# DA1470x register map
Vendor: Dialog; Series: DA1470x; File version: 1.2
CPU: CM33 r0p2, little endian, MPU, FPU, DSP, VTOR, 4 interrupt priority bits
Registers are 32-bit, read-write, reset 0x0 unless marked. A register's access mark holds for its fields unless they carry their own. Offsets are from the block's base; [hi:lo] are bit positions; {n}, {i} and the like mark numbered series.

## MEMCTRL — MEMCTRL registers
Base 0x50050000
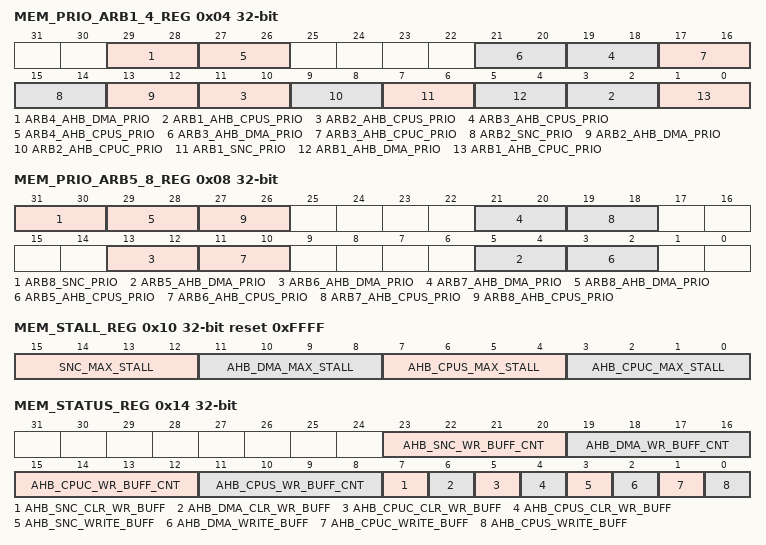
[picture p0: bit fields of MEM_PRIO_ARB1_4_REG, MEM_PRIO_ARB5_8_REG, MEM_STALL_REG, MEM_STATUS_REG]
0x04 MEM_PRIO_ARB1_4_REG — Priority Control Register for arbiter 1, 2, 3 and 4
  [29:28] ARB4_AHB_DMA_PRIO — Priority for the DMA AHB interface of arbiter 4 00: low priority (default) 01: mid priority 1x: high priority
  [8n-5:8n-6] ARB{n}_AHB_CPUS_PRIO (n=1..4) — Priority for the CPUS AHB interface of arbiter {n}. 00: low priority (default) 01: mid priority 10: high priority 11: top priority
  [21:20] ARB3_AHB_DMA_PRIO — Priority for the DMA AHB interface of arbiter 3 00: low priority (default) 01: mid priority 1x: high priority
  [17:16] ARB3_AHB_CPUC_PRIO — Priority for the CPUC AHB interface of arbiter 3. 00: low priority (default) 01: mid priority 10: high priority 11: top priority
  [15:14] ARB2_SNC_PRIO — Priority for the SNC interface of arbiter 2. 00: low priority (default) 01: mid priority 10: high priority 11: top priority
  [13:12] ARB2_AHB_DMA_PRIO — Priority for the DMA AHB interface of arbiter 2. 00: low priority (default) 01: mid priority 1x: high priority
  [9:8] ARB2_AHB_CPUC_PRIO — Priority for the CPUC AHB interface of arbiter 2. 00: low priority (default) 01: mid priority 10: high priority 11: top priority
  [7:6] ARB1_SNC_PRIO — Priority for the SNC interface of arbiter 1. 00: low priority (default) 01: mid priority 10: high priority 11: top priority
  [5:4] ARB1_AHB_DMA_PRIO — Priority for the DMA AHB interface of arbiter 1. 00: low priority (default) 01: mid priority 1x: high priority
  [1:0] ARB1_AHB_CPUC_PRIO — Priority for the CPUC AHB interface of arbiter 1. 00: low priority (default) 01: mid priority 10: high priority 11: top priority
0x08 MEM_PRIO_ARB5_8_REG (reset mask 0x7FFFFFFF) — Priority Control Register for arbiter 5, 6, 7 and 8
  [31:30] ARB8_SNC_PRIO — Priority for the SNC interface of arbiter 8. 00: low priority (default) 01: mid priority 10: high priority 11: top priority
  [8n-35:8n-36] ARB{n}_AHB_DMA_PRIO (n=5..8) — Priority for the DMA AHB interface of arbiter {n}. 00: low priority (default) 01: mid priority 1x: high priority
  [8n-37:8n-38] ARB{n}_AHB_CPUS_PRIO (n=5..8) — Priority for the CPUS AHB interface of arbiter {n}. 00: low priority (default) 01: mid priority 10: high priority 11: top priority
0x10 MEM_STALL_REG reset 0xFFFF — Maximum Stall cycles Control Register
  [15:12] SNC_MAX_STALL — Maximum allowed number of stall cycles for the SNC interface. If exceeded, the interface will get high priority. Valid for a single access so the next access (of a burst) might end up in the que for the same number of wait cycles. 0: don't use, not feasible and can block other interfaces 1: max 1 stall cycle 15: max 15 stall cycles
  [11:8] AHB_DMA_MAX_STALL — Maximum allowed number of stall cycles for the DMA AHB interface. If exceeded, the interface will get high priority. Valid for a single access so the next access (of a burst) might end up in the que for the same number of wait cycles. 0: don't use, not feasible and can block other interfaces 1: max 1 stall cycle 15: max 15 stall cycles
  [7:4] AHB_CPUS_MAX_STALL — Maximum allowed number of stall cycles for the CPUS AHB interface. If exceeded, the interface will get high priority. Valid for a single access so the next access (of a burst) might end up in the que for the same number of wait cycles. 0: don't use, not feasible and can block other interfaces 1: max 1 stall cycle 15: max 15 stall cycles
  [3:0] AHB_CPUC_MAX_STALL — Maximum allowed number of stall cycles for the CPUC AHB interface. If exceeded, the interface will get high priority. Valid for a single access so the next access (of a burst) might end up in the que for the same number of wait cycles. 0: don't use, not feasible and can block other interfaces 1: max 1 stall cycle 15: max 15 stall cycles
0x14 MEM_STATUS_REG — Memory Arbiter Status Register
  [23:20] AHB_SNC_WR_BUFF_CNT ro — The maximum number of arbiter clock cycles that an SNC AHB access has been buffered.
  [19:16] AHB_DMA_WR_BUFF_CNT ro — The maximum number of arbiter clock cycles that an DMA AHB access has been buffered.
  [15:12] AHB_CPUC_WR_BUFF_CNT ro — The maximum number of arbiter clock cycles that an CPUC AHB access has been buffered.
  [11:8] AHB_CPUS_WR_BUFF_CNT ro — The maximum number of arbiter clock cycles that an CPUS_AHB access has been buffered.
  [7] AHB_SNC_CLR_WR_BUFF wo — Writing a '1' clears AHB_SNC_WR_BUFF_CNT.
  [6] AHB_DMA_CLR_WR_BUFF wo — Writing a '1' clears AHB_DMA_WR_BUFF_CNT.
  [5] AHB_CPUC_CLR_WR_BUFF wo — Writing a '1' clears AHB_CPUC_WR_BUFF_CNT.
  [4] AHB_CPUS_CLR_WR_BUFF wo — Writing a '1' clears AHB_CPUS_WR_BUFF_CNT.
  [3] AHB_SNC_WRITE_BUFF ro — 0: No SNC AHB write access is buffered. 1: Currently a single SNC AHB write access is buffered in the arbiter.
  [2] AHB_DMA_WRITE_BUFF ro — 0: No DMA AHB write access is buffered. 1: Currently a single DMA AHB write access is buffered in the arbiter.
  [1] AHB_CPUC_WRITE_BUFF ro — 0: No CPUC AHB write access is buffered. 1: Currently a single CPUC AHB write access is buffered in the arbiter.
  [0] AHB_CPUS_WRITE_BUFF ro — 0: No CPUS AHB write access is buffered. 1: Currently a single CPUS AHB write access is buffered in the arbiter.
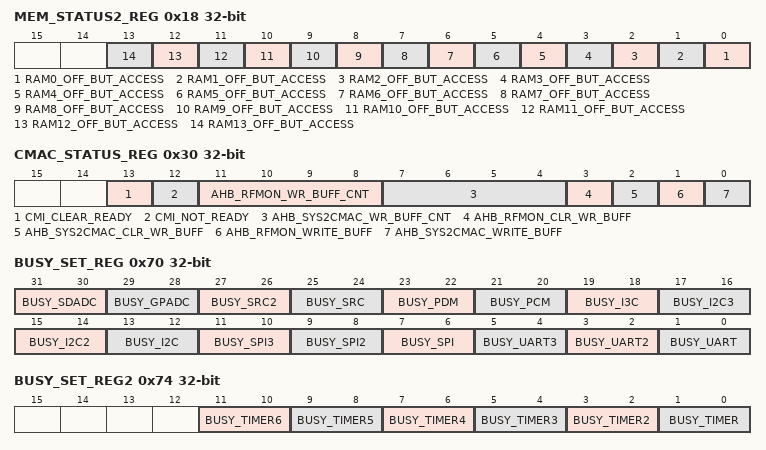
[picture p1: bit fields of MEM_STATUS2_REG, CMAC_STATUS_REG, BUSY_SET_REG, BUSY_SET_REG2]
0x18 MEM_STATUS2_REG — RAM cells Status Register
  [n] RAM{n}_OFF_BUT_ACCESS (n=0..13) — Reading a '1' indicates RAM{n} was off but still access was performed. Writing a '1' will clear the status back to '0'.
0x20 CMI_CODE_BASE_REG — CMAC code Base Address Register
  [19:10] CMI_CODE_BASE_ADDR ro — Base address for CMAC code with steps of 1 kB. 0x001: 1 kB base address 0x010: 16 kB base address 0x100: 256 kB base address
0x24 CMI_DATA_BASE_REG — CMAC data Base Address Register
  [19:2] CMI_DATA_BASE_ADDR — Base address for CMAC data with steps of 4 bytes. Note that the CMAC address scheme is used. 0x00001: 4 byte base address 0x00010: 64 byte base address 0x00100: 1 kB base address 0x01000: 16 kB base address 0x10000: 256 kB base address
0x28 CMI_SHARED_BASE_REG — CMAC shared data Base Address Register
  [19:10] CMI_SHARED_BASE_ADDR — Base address for CMAC shared data with steps of 1 kB. Note that the CMAC address scheme is used and should only be used to point to RAM 9 or 10.. 0x001: 1 kB base address 0x010: 16 kB base address 0x100: 256 kB base address
0x2C CMI_END_REG reset 0xFFFFF — CMAC end Address Register
  [19:10] CMI_END_ADDR — End address for CMAC code and data accesses with steps of 1 kB. Note that the CMAC address scheme is used. 0x000: accesses up to 1kB are allowed 0x001: accesses up to 2kB are allowed 0x01F: accesses up to 32kB are allowed 0x1FF: accesses up to 512kB are allowed
0x30 CMAC_STATUS_REG — Memory Arbiter Status Register
  [13] CMI_CLEAR_READY wo — Writing a '1' clears CMI_NOT_READY bit.
  [12] CMI_NOT_READY ro — 0: Normal operation 1: CMI access performed which couldn't be handled right away (interface doesn't allow wait cycles)
  [11:8] AHB_RFMON_WR_BUFF_CNT ro — The maximum number of arbiter clock cycles that an CPUC AHB access has been buffered.
  [7:4] AHB_SYS2CMAC_WR_BUFF_CNT ro — The maximum number of arbiter clock cycles that an CPUS_AHB access has been buffered.
  [3] AHB_RFMON_CLR_WR_BUFF wo — Writing a '1' clears AHB_CPUC_WR_BUFF_CNT.
  [2] AHB_SYS2CMAC_CLR_WR_BUFF wo — Writing a '1' clears AHB_CPUS_WR_BUFF_CNT.
  [1] AHB_RFMON_WRITE_BUFF ro — 0: No CPUC AHB write access is buffered. 1: Currently a single CPUC AHB write access is buffered in the arbiter.
  [0] AHB_SYS2CMAC_WRITE_BUFF ro — 0: No CPUS AHB write access is buffered. 1: Currently a single CPUS AHB write access is buffered in the arbiter.
0x70 BUSY_SET_REG (reset mask 0x7FFFFFFF) — BSR Set Register
  [31:30] BUSY_SDADC write-once — Writing a non-zero value to this field sets the corresponding BUSY bit, but only if it was not claimed (BUSY=0). Reading returns 0 to allow read/modify/write to the register.
  [29:28] BUSY_GPADC write-once — Writing a non-zero value to this field sets the corresponding BUSY bit, but only if it was not claimed (BUSY=0). Reading returns 0 to allow read/modify/write to the register.
  [27:26] BUSY_SRC2 write-once — Writing a non-zero value to this field sets the corresponding BUSY bit, but only if it was not claimed (BUSY=0). Reading returns 0 to allow read/modify/write to the register.
  [25:24] BUSY_SRC write-once — Writing a non-zero value to this field sets the corresponding BUSY bit, but only if it was not claimed (BUSY=0). Reading returns 0 to allow read/modify/write to the register.
  [23:22] BUSY_PDM write-once — Writing a non-zero value to this field sets the corresponding BUSY bit, but only if it was not claimed (BUSY=0). Reading returns 0 to allow read/modify/write to the register.
  [21:20] BUSY_PCM write-once — Writing a non-zero value to this field sets the corresponding BUSY bit, but only if it was not claimed (BUSY=0). Reading returns 0 to allow read/modify/write to the register.
  [19:18] BUSY_I3C write-once — Writing a non-zero value to this field sets the corresponding BUSY bit, but only if it was not claimed (BUSY=0). Reading returns 0 to allow read/modify/write to the register.
  [17:16] BUSY_I2C3 write-once — Writing a non-zero value to this field sets the corresponding BUSY bit, but only if it was not claimed (BUSY=0). Reading returns 0 to allow read/modify/write to the register.
  [15:14] BUSY_I2C2 write-once — Writing a non-zero value to this field sets the corresponding BUSY bit, but only if it was not claimed (BUSY=0). Reading returns 0 to allow read/modify/write to the register.
  [13:12] BUSY_I2C write-once — Writing a non-zero value to this field sets the corresponding BUSY bit, but only if it was not claimed (BUSY=0). Reading returns 0 to allow read/modify/write to the register.
  [11:10] BUSY_SPI3 write-once — Writing a non-zero value to this field sets the corresponding BUSY bit, but only if it was not claimed (BUSY=0). Reading returns 0 to allow read/modify/write to the register.
  [9:8] BUSY_SPI2 write-once — Writing a non-zero value to this field sets the corresponding BUSY bit, but only if it was not claimed (BUSY=0). Reading returns 0 to allow read/modify/write to the register.
  [7:6] BUSY_SPI write-once — Writing a non-zero value to this field sets the corresponding BUSY bit, but only if it was not claimed (BUSY=0). Reading returns 0 to allow read/modify/write to the register.
  [5:4] BUSY_UART3 write-once — Writing a non-zero value to this field sets the corresponding BUSY bit, but only if it was not claimed (BUSY=0). Reading returns 0 to allow read/modify/write to the register.
  [3:2] BUSY_UART2 write-once — Writing a non-zero value to this field sets the corresponding BUSY bit, but only if it was not claimed (BUSY=0). Reading returns 0 to allow read/modify/write to the register.
  [1:0] BUSY_UART write-once — Writing a non-zero value to this field sets the corresponding BUSY bit, but only if it was not claimed (BUSY=0). Reading returns 0 to allow read/modify/write to the register.
0x74 BUSY_SET_REG2 — BSR2 Set Register
  [2n-1:2n-2] BUSY_TIMER{n} write-once (n=2..6) — Writing a non-zero value to this field sets the corresponding BUSY bit, but only if it was not claimed (BUSY=0). Reading returns 0 to allow read/modify/write to the register.
  [1:0] BUSY_TIMER write-once — Writing a non-zero value to this field sets the corresponding BUSY bit, but only if it was not claimed (BUSY=0). Reading returns 0 to allow read/modify/write to the register.
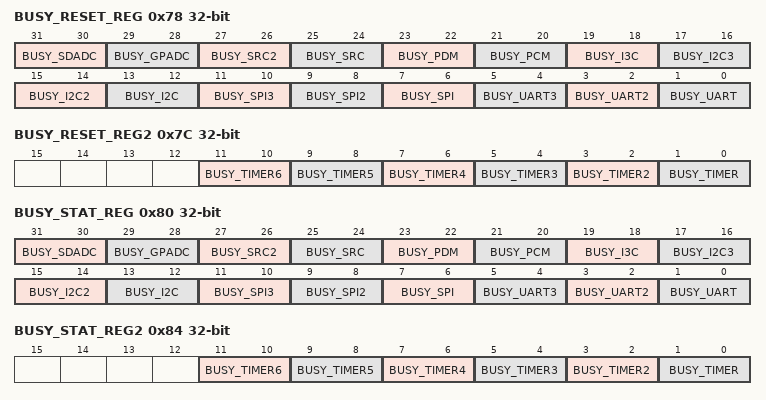
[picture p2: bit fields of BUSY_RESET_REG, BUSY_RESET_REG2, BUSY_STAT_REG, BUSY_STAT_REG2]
0x78 BUSY_RESET_REG (reset mask 0x7FFFFFFF) — BSR Reset Register
  [31:30] BUSY_SDADC — Clear the BUSY bitfield, by writing the master code which has claimed to this field Reading returns 0 to allow read/modify/write to the register.
  [29:28] BUSY_GPADC — Clear the BUSY bitfield, by writing the master code which has claimed to this field Reading returns 0 to allow read/modify/write to the register.
  [27:26] BUSY_SRC2 — Clear the BUSY bitfield, by writing the master code which has claimed to this field Reading returns 0 to allow read/modify/write to the register.
  [25:24] BUSY_SRC — Clear the BUSY bitfield, by writing the master code which has claimed to this field Reading returns 0 to allow read/modify/write to the register.
  [23:22] BUSY_PDM — Clear the BUSY bitfield, by writing the master code which has claimed to this field Reading returns 0 to allow read/modify/write to the register.
  [21:20] BUSY_PCM — Clear the BUSY bitfield, by writing the master code which has claimed to this field Reading returns 0 to allow read/modify/write to the register.
  [19:18] BUSY_I3C — Clear the BUSY bitfield, by writing the master code which has claimed to this field Reading returns 0 to allow read/modify/write to the register.
  [17:16] BUSY_I2C3 — Clear the BUSY bitfield, by writing the master code which has claimed to this field Reading returns 0 to allow read/modify/write to the register.
  [15:14] BUSY_I2C2 — Clear the BUSY bitfield, by writing the master code which has claimed to this field Reading returns 0 to allow read/modify/write to the register.
  [13:12] BUSY_I2C — Clear the BUSY bitfield, by writing the master code which has claimed to this field Reading returns 0 to allow read/modify/write to the register.
  [11:10] BUSY_SPI3 — Clear the BUSY bitfield, by writing the master code which has claimed to this field Reading returns 0 to allow read/modify/write to the register.
  [9:8] BUSY_SPI2 — Clear the BUSY bitfield, by writing the master code which has claimed to this field Reading returns 0 to allow read/modify/write to the register.
  [7:6] BUSY_SPI — Clear the BUSY bitfield, by writing the master code which has claimed to this field Reading returns 0 to allow read/modify/write to the register.
  [5:4] BUSY_UART3 — Clear the BUSY bitfield, by writing the master code which has claimed to this field Reading returns 0 to allow read/modify/write to the register.
  [3:2] BUSY_UART2 — Clear the BUSY bitfield, by writing the master code which has claimed to this field Reading returns 0 to allow read/modify/write to the register.
  [1:0] BUSY_UART — Clear the BUSY bitfield, by writing the master code which has claimed to this field Reading returns 0 to allow read/modify/write to the register.
0x7C BUSY_RESET_REG2 — BSR2 Reset Register
  [2n-1:2n-2] BUSY_TIMER{n} (n=2..6) — Clear the BUSY bitfield, by writing the master code which has claimed to this field Reading returns 0 to allow read/modify/write to the register.
  [1:0] BUSY_TIMER — Clear the BUSY bitfield, by writing the master code which has claimed to this field Reading returns 0 to allow read/modify/write to the register.
0x80 BUSY_STAT_REG (reset mask 0x7FFFFFFF) — BSR Status Register
  [31:30] BUSY_SDADC ro — A non-zero value indicates the resource is busy. The value represents which master is using it.
  [29:28] BUSY_GPADC ro — A non-zero value indicates the resource is busy. The value represents which master is using it.
  [27:26] BUSY_SRC2 ro — A non-zero value indicates the resource is busy. The value represents which master is using it.
  [25:24] BUSY_SRC ro — A non-zero value indicates the resource is busy. The value represents which master is using it.
  [23:22] BUSY_PDM ro — A non-zero value indicates the resource is busy. The value represents which master is using it.
  [21:20] BUSY_PCM ro — A non-zero value indicates the resource is busy. The value represents which master is using it.
  [19:18] BUSY_I3C ro — A non-zero value indicates the resource is busy. The value represents which master is using it.
  [17:16] BUSY_I2C3 ro — A non-zero value indicates the resource is busy. The value represents which master is using it.
  [15:14] BUSY_I2C2 ro — A non-zero value indicates the resource is busy. The value represents which master is using it.
  [13:12] BUSY_I2C ro — A non-zero value indicates the resource is busy. The value represents which master is using it.
  [11:10] BUSY_SPI3 ro — A non-zero value indicates the resource is busy. The value represents which master is using it.
  [9:8] BUSY_SPI2 ro — A non-zero value indicates the resource is busy. The value represents which master is using it.
  [7:6] BUSY_SPI ro — A non-zero value indicates the resource is busy. The value represents which master is using it.
  [5:4] BUSY_UART3 ro — A non-zero value indicates the resource is busy. The value represents which master is using it.
  [3:2] BUSY_UART2 ro — A non-zero value indicates the resource is busy. The value represents which master is using it.
  [1:0] BUSY_UART ro — A non-zero value indicates the resource is busy. The value represents which master is using it.
0x84 BUSY_STAT_REG2 — BSR2 Status Register
  [2n-1:2n-2] BUSY_TIMER{n} ro (n=2..6) — A non-zero value indicates the resource is busy. The value represents which master is using it.
  [1:0] BUSY_TIMER ro — A non-zero value indicates the resource is busy. The value represents which master is using it.
